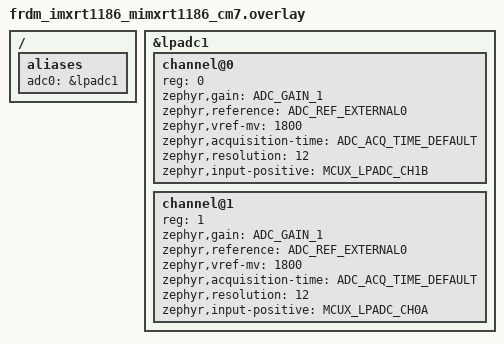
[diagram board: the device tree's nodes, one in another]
/*
 * Copyright 2026 NXP
 *
 * SPDX-License-Identifier: Apache-2.0
 */

#include <zephyr/dt-bindings/adc/adc.h>
#include <zephyr/dt-bindings/adc/mcux-lpadc.h>

/ {
	aliases {
		adc0 = &lpadc1;
	};
};

&lpadc1 {
	#address-cells = <1>;
	#size-cells = <0>;

	/* Channel 0: GPIO_AD_15 (ADC1_CH1B) via J51-2 */
	channel@0 {
		reg = <0>;
		zephyr,gain = "ADC_GAIN_1";
		zephyr,reference = "ADC_REF_EXTERNAL0";
		zephyr,vref-mv = <1800>;
		zephyr,acquisition-time = <ADC_ACQ_TIME_DEFAULT>;
		zephyr,resolution = <12>;
		zephyr,input-positive = <MCUX_LPADC_CH1B>;
	};

	/* Channel 1: GPIO_AD_16 (ADC1_CH0A) via J51-4, ensure J28 is in 2-3 position */
	channel@1 {
		reg = <1>;
		zephyr,gain = "ADC_GAIN_1";
		zephyr,reference = "ADC_REF_EXTERNAL0";
		zephyr,vref-mv = <1800>;
		zephyr,acquisition-time = <ADC_ACQ_TIME_DEFAULT>;
		zephyr,resolution = <12>;
		zephyr,input-positive = <MCUX_LPADC_CH0A>;
	};
};
